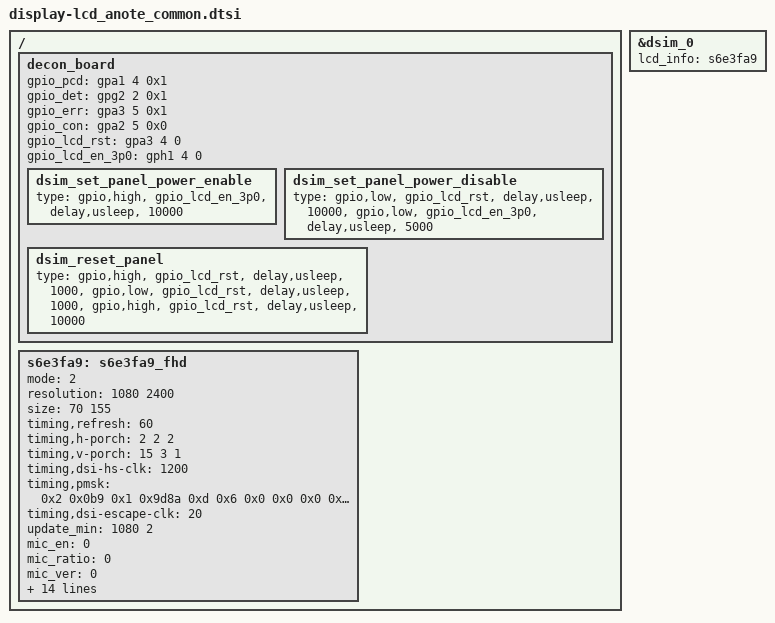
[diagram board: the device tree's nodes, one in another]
/*
 * SAMSUNG LCD Panel Device Tree Source
 *
 * Copyright (c) 2017 Samsung Electronics Co., Ltd.
 *		http://www.samsung.com
 *
 * This program is free software; you can redistribute it and/or modify
 * it under the terms of the GNU General Public License version 2 as
 * published by the Free Software Foundation.
 */

/ {
	fragment@lcd {
		target-path = "/";
		__overlay__ {
			decon_board: decon_board {
				gpio_pcd = <&gpa1 4 0x1>;	/* PCD_INT */
				gpio_det = <&gpg2 2 0x1>;	/* EL_ON1_DET */
				gpio_err = <&gpa3 5 0x1>;	/* FG_ERR */
				gpio_con = <&gpa2 5 0x0>;	/* OCTA_CON_DET */

				gpio_lcd_rst = <&gpa3 4 0>;
				gpio_lcd_en_3p0 = <&gph1 4 0>;

				dsim_set_panel_power_enable {
					type =
					"gpio,high",	"gpio_lcd_en_3p0",
					"delay,usleep",	"10000";
				};
				dsim_set_panel_power_disable {
					type =
					"gpio,low",	"gpio_lcd_rst",
					"delay,usleep",	"10000",
					"gpio,low",	"gpio_lcd_en_3p0",
					"delay,usleep",	"5000";
				};
				dsim_reset_panel {
					type =
					"gpio,high",	"gpio_lcd_rst",
					"delay,usleep",	"1000",
					"gpio,low",	"gpio_lcd_rst",
					"delay,usleep",	"1000",
					"gpio,high",	"gpio_lcd_rst",
					"delay,usleep",	"10000";
				};
			};

			s6e3fa9: s6e3fa9_fhd {
				mode = <2>; /* 0: video mode, 1: DP command mode, 2: MIPI command mode */
				resolution = <1080 2400>;
				size = <70 155>;	/* 69.552 * 154.56 */
				timing,refresh = <60>;
				timing,h-porch = <2 2 2>;
				timing,v-porch = <15 3 1>;
				timing,dsi-hs-clk = <1200>;
				timing,pmsk = <
					0x2 0x0b9 0x1 0x9d8a /* p m s k */
					0xd 0x6	  0x0 0x0    /* mfr mrr sel_pf icp */
					0x0 0x0   0x0 0x0    /* afc_enb extafc feed_en fsel */
					0x0 0x0              /* fout_mask rsel */
				>;
				timing,dsi-escape-clk = <20>;
				update_min = <1080 2>;
				mic_en = <0>;		/* 0: Disable, 1: Enable */
				mic_ratio = <0>;	/* 0: 1/2 mic, 1: 1/3 mic */
				mic_ver = <0>;		/* 0: mic v1.1, 1: v1.2, 2: v2.0 */
				type_of_ddi = <0>;	/* 0: Samsung Mobile, 1: MAGNA, 2: Normal(Etc) */
				dsc_en = <0>;		/* 0: Disable, 1: Enable */
				dsc_cnt = <0>;		/* used DSC count */
				dsc_slice_num = <0>;	/* count of dsc slice */
				data_lane = <4>;	/* number of using data lane */
				cmd_underrun_lp_ref = <1463>;	/* for underrun detect at command mode */
				mres_en = <0>;
				noncontinuous_clklane = <0>;	/* 0: Disable, 1: Enable */
				hdr_num = <2>;		/* max: 4 */
				hdr_type = <2 3 0 0>;	/* 1: DOLBY_VISION, 2: HDR10, 3: HLG */
				hdr_max_luma = <5400000>;		/* 540 */
				hdr_max_avg_luma = <1200000>;	/* 120 */
				hdr_min_luma = <5>;				/* 0.0005 */
				decon_board = <&decon_board>;
			};
		};
	};
};

&dsim_0 {
	lcd_info = <&s6e3fa9>;
};

